# STM32N657 register map
File version: 1.0
CPU: CM55 r0p1, little endian, no MPU, FPU, vendor SysTick, 8 interrupt priority bits
Registers are 32-bit, read-write, reset 0x0 unless marked. A register's access mark holds for its fields unless they carry their own. Offsets are from the block's base; [hi:lo] are bit positions; {n}, {i} and the like mark numbered series; 'fields as' and 'values as' point back to an identical list.

## RISAF — Resource isolation slave unit for address space protection
Base 0x44026000
Same registers: RISAF_S 0x54026000
0x00 CR — RISAF configuration register
  [0] GLOCK — global lock
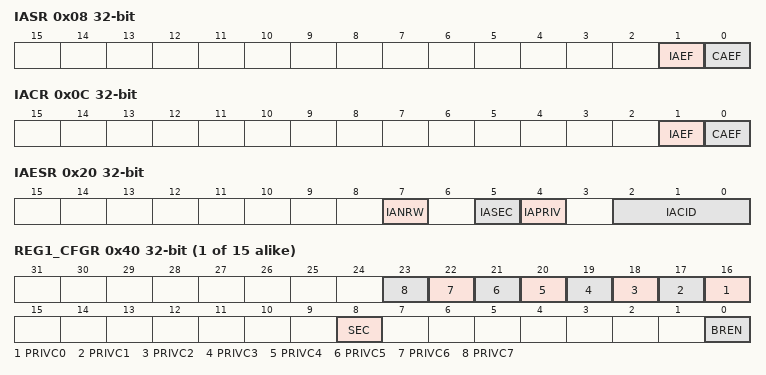
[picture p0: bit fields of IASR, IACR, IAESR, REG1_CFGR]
0x08 IASR ro — RISAF illegal access status register
  [1] IAEF — illegal access error flag
  [0] CAEF — configuration access error flag
0x0C IACR wo — RISAF illegal access clear register
  fields as IASR
0x20 IAESR ro — RISAF illegal access error status register
  [7] IANRW — illegal access read/write
  [5] IASEC — illegal access security
  [4] IAPRIV — illegal access privileged
  [2:0] IACID — illegal access compartment ID
0x24 IADDR ro — RISAF illegal address register
  [31:0] IADD — illegal address
{0x0+0x40*i} REG{i}_CFGR (i=1..15) — RISAF region {i} configuration register
  [n+16] PRIVC{n} (n=0..7) — privileged access for compartment y
  [8] SEC — secure region
  [0] BREN — base region enable
{0x4+0x40*i} REG{i}_STARTR (i=1..15) — RISAF region {i} start-address register
  [31:0] BADDSTART — Base region address start
{0x8+0x40*i} REG{i}_ENDR reset 0xFFF (i=1..15) — RISAF region {i} end-address register
  [31:0] BADDEND — Base region address end
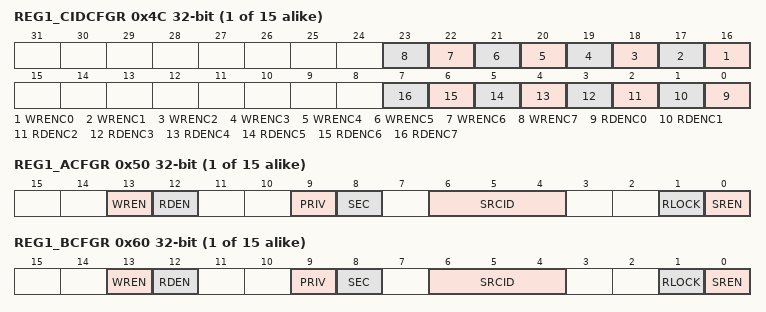
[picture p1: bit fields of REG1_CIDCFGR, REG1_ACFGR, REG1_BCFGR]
{0xC+0x40*i} REG{i}_CIDCFGR (i=1..15) — RISAF region {i} CID configuration register
  [n+16] WRENC{n} (n=0..7) — write enable for compartment y
  [n] RDENC{n} (n=0..7) — read enable for compartment y
{0x10+0x40*i} REG{i}_ACFGR (i=1..15) — RISAF region {i} subregion A configuration register
  [13] WREN — write enable
  [12] RDEN — read enable
  [9] PRIV — privileged subregion
  [8] SEC — secure subregion
  [6:4] SRCID — subregion CID
  [1] RLOCK — resource lock
  [0] SREN — subregion enable
{0x14+0x40*i} REG{i}_ASTARTR (i=1..15) — RISAF region {i} subregion A start-address register
  [31:0] SADDSTART — subregion address start
{0x18+0x40*i} REG{i}_AENDR reset 0xFFF (i=1..15) — RISAF region {i} subregion A end-address register
  [31:0] SADDEND — subregion address end
{0x1C+0x40*i} REG{i}_ANESTR (i=1..15) — RISAF region {i} subregion A nested mode register
  [2] DCEN — delegated configuration enable
{0x20+0x40*i} REG{i}_BCFGR (i=1..15) — RISAF region {i} subregion B configuration register
  fields as REG1_ACFGR
{0x24+0x40*i} REG{i}_BSTARTR (i=1..15) — RISAF region {i} subregion B start-address register
  [31:0] SADDSTART — subregion address start
{0x28+0x40*i} REG{i}_BENDR reset 0xFFF (i=1..15) — RISAF region {i} subregion B end-address register
  [31:0] SADDEND — subregion address end
{0x2C+0x40*i} REG{i}_BNESTR (i=1..15) — RISAF region {i} subregion B nested mode register
  [2] DCEN — delegated configuration enable

## SAES — Secure AES coprocessor
Base 0x44021000
Same registers: SAES_S 0x54021000
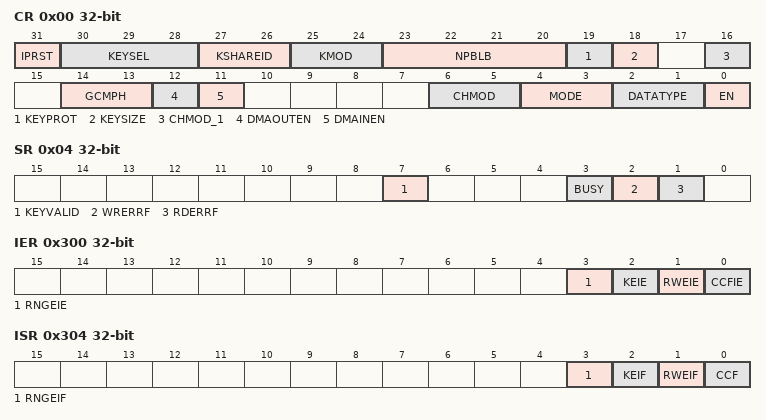
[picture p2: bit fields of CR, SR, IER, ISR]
0x00 CR — SAES control register
  [31] IPRST — SAES peripheral software reset
  [30:28] KEYSEL — Key selection
  [27:26] KSHAREID — Key share identification
  [25:24] KMOD — Key mode selection
  [23:20] NPBLB — Number of padding bytes in last block
  [19] KEYPROT — Key protection
  [18] KEYSIZE — Key size selection
  [16] CHMOD_1 — CHMOD[2]
  [14:13] GCMPH — GCM or CCM phase selection
  [12] DMAOUTEN — DMA output enable
  [11] DMAINEN — DMA input enable
  [6:5] CHMOD — CHMOD[1:0]: Chaining mode
  [4:3] MODE — Operating mode
  [2:1] DATATYPE
  [0] EN — Enable
0x04 SR ro — SAES status register
  [7] KEYVALID — Key valid flag
  [3] BUSY
  [2] WRERRF — Write error flag
  [1] RDERRF — Read error flag
0x08 DINR wo — SAES data input register
  [31:0] DIN — Data input
0x0C DOUTR ro — SAES data output register
  [31:0] DOUT — Data output
{0x10+4i} KEYR{i} wo (i=0..3) — SAES key register {i}
  [31:0] KEY — Cryptographic key, bits [{32i+31}:{32i}]
{0x20+4i} IVR{i} (i=0..3) — SAES initialization vector register {i}
  [31:0] IVI — Initialization vector input, bits [{32i+31}:{32i}]
{0x20+4i} KEYR{i} wo (i=4..7) — SAES key register {i}
  [31:0] KEY — Cryptographic key, bits [{32i+31}:{32i}]
{0x40+4i} SUSPR{i} (i=0..7) — SAES suspend registers
  [31:0] SUSP — Suspend data
0x300 IER — SAES interrupt enable register
  [3] RNGEIE — RNG error interrupt enable
  [2] KEIE — Key error interrupt enable
  [1] RWEIE — Read or write error interrupt enable
  [0] CCFIE — Computation complete flag interrupt enable
0x304 ISR ro — SAES interrupt status register
  [3] RNGEIF — RNG error interrupt flag
  [2] KEIF — Key error interrupt flag
  [1] RWEIF — Read or write error interrupt flag
  [0] CCF — Computation complete flag
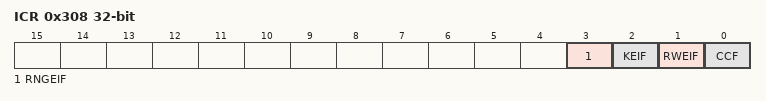
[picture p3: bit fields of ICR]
0x308 ICR wo — SAES interrupt clear register
  [3] RNGEIF — RNG error interrupt flag clear
  [2] KEIF — Key error interrupt flag clear
  [1] RWEIF — Read or write error interrupt flag clear
  [0] CCF — Computation complete flag clear
